AUTOSAR XML (schema 4-2-2)
package /Components
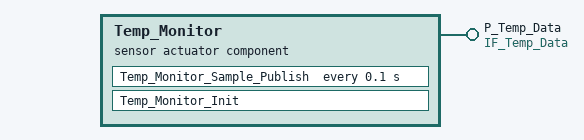
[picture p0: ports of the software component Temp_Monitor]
  sensor actuator sw component type Temp_Monitor
    provide port P_Temp_Data: provided-interface=IF_Temp_Data
    behavior Temp_Monitor_InternalBehavior
      data receive error event Temp_Monitor_Sensor_Error: start-on-event=Temp_Monitor_Sample_Publish
      init event Temp_Monitor_Init_Event: start-on-event=Temp_Monitor_Init
      timing event Temp_Monitor_Periodic_100ms: start-on-event=Temp_Monitor_Sample_Publish, period=0.1
      runnable Temp_Monitor_Init: symbol=R_Temp_Monitor_Init
        data-send-points:
          13 x access:
            VA_Send_t_motor: accessed-variable=P_Temp_Data.t_motor
            VA_Send_t_inverter: accessed-variable=P_Temp_Data.t_inverter
            VA_Send_t_battery_pack: accessed-variable=P_Temp_Data.t_battery_pack
            VA_Send_t_batt_coolant_in: accessed-variable=P_Temp_Data.t_batt_coolant_in
            VA_Send_t_batt_coolant_out: accessed-variable=P_Temp_Data.t_batt_coolant_out
            VA_Send_t_cabin_ambient: accessed-variable=P_Temp_Data.t_cabin_ambient
            VA_Send_t_evap_outlet: accessed-variable=P_Temp_Data.t_evap_outlet
            VA_Send_t_heater_core: accessed-variable=P_Temp_Data.t_heater_core
            VA_Send_t_radiator_outlet: accessed-variable=P_Temp_Data.t_radiator_outlet
            VA_Send_t_pump{1..3}_housing: accessed-variable=P_Temp_Data.t_pump{1..3}_housing
            VA_Send_t_battery_pack_dup: accessed-variable=P_Temp_Data.t_battery_pack
        data-write-access:
          12 x access:
            VA_Write_t_motor: accessed-variable=P_Temp_Data.t_motor
            VA_Write_t_inverter: accessed-variable=P_Temp_Data.t_inverter
            VA_Write_t_battery_pack: accessed-variable=P_Temp_Data.t_battery_pack
            VA_Write_t_batt_coolant_in: accessed-variable=P_Temp_Data.t_batt_coolant_in
            VA_Write_t_batt_coolant_out: accessed-variable=P_Temp_Data.t_batt_coolant_out
            VA_Write_t_cabin_ambient: accessed-variable=P_Temp_Data.t_cabin_ambient
            VA_Write_t_evap_outlet: accessed-variable=P_Temp_Data.t_evap_outlet
            VA_Write_t_heater_core: accessed-variable=P_Temp_Data.t_heater_core
            VA_Write_t_radiator_outlet: accessed-variable=P_Temp_Data.t_radiator_outlet
            VA_Write_t_pump{1..3}_housing: accessed-variable=P_Temp_Data.t_pump{1..3}_housing
      runnable Temp_Monitor_Sample_Publish: minimum-start-interval=0.1, symbol=R_Temp_Monitor_Sample_Publish
        data-send-points:
          12 x access:
            VA_Send_t_motor: accessed-variable=P_Temp_Data.t_motor
            VA_Send_t_inverter: accessed-variable=P_Temp_Data.t_inverter
            VA_Send_t_battery_pack: accessed-variable=P_Temp_Data.t_battery_pack
            VA_Send_t_batt_coolant_in: accessed-variable=P_Temp_Data.t_batt_coolant_in
            VA_Send_t_batt_coolant_out: accessed-variable=P_Temp_Data.t_batt_coolant_out
            VA_Send_t_cabin_ambient: accessed-variable=P_Temp_Data.t_cabin_ambient
            VA_Send_t_evap_outlet: accessed-variable=P_Temp_Data.t_evap_outlet
            VA_Send_t_heater_core: accessed-variable=P_Temp_Data.t_heater_core
            VA_Send_t_radiator_outlet: accessed-variable=P_Temp_Data.t_radiator_outlet
            VA_Send_t_pump{1..3}_housing: accessed-variable=P_Temp_Data.t_pump{1..3}_housing
        data-write-access:
          12 x access:
            VA_Write_t_motor: accessed-variable=P_Temp_Data.t_motor
            VA_Write_t_inverter: accessed-variable=P_Temp_Data.t_inverter
            VA_Write_t_battery_pack: accessed-variable=P_Temp_Data.t_battery_pack
            VA_Write_t_batt_coolant_in: accessed-variable=P_Temp_Data.t_batt_coolant_in
            VA_Write_t_batt_coolant_out: accessed-variable=P_Temp_Data.t_batt_coolant_out
            VA_Write_t_cabin_ambient: accessed-variable=P_Temp_Data.t_cabin_ambient
            VA_Write_t_evap_outlet: accessed-variable=P_Temp_Data.t_evap_outlet
            VA_Write_t_heater_core: accessed-variable=P_Temp_Data.t_heater_core
            VA_Write_t_radiator_outlet: accessed-variable=P_Temp_Data.t_radiator_outlet
            VA_Write_t_pump{1..3}_housing: accessed-variable=P_Temp_Data.t_pump{1..3}_housing
